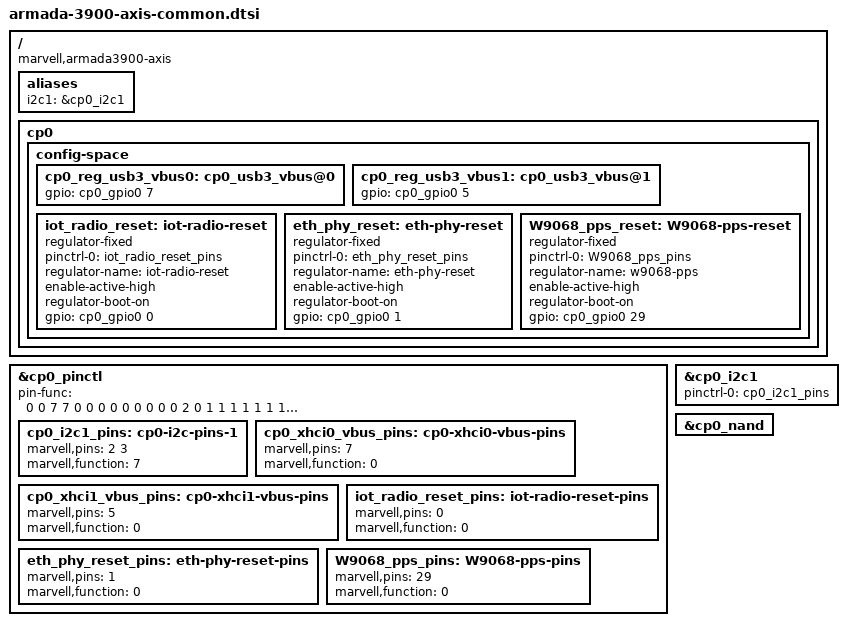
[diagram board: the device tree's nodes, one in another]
/*
 * Copyright (C) 2018 Marvell International Ltd.
 *
 * SPDX-License-Identifier:    GPL-2.0
 * https://spdx.org/licenses
 */

#include "armada-3900-db.dtsi"

/ {
	compatible = "marvell,armada3900-axis", "marvell,armada7040",
		     "marvell,armada-ap806-quad", "marvell,armada-ap806";

	aliases {
		i2c1 = &cp0_i2c1;
	};

	cp0 {
		config-space {
			cp0_reg_usb3_vbus0: cp0_usb3_vbus@0 {
				gpio = <&cp0_gpio0 7 GPIO_ACTIVE_HIGH>;
			};

			cp0_reg_usb3_vbus1: cp0_usb3_vbus@1 {
				gpio = <&cp0_gpio0 5 GPIO_ACTIVE_HIGH>;
			};

			iot_radio_reset: iot-radio-reset {
				compatible = "regulator-fixed";
				pinctrl-names = "default";
				pinctrl-0 = <&iot_radio_reset_pins>;
				regulator-name = "iot-radio-reset";
				enable-active-high;
				regulator-boot-on;
				gpio = <&cp0_gpio0 0 GPIO_ACTIVE_HIGH>;
			};

			eth_phy_reset: eth-phy-reset {
				compatible = "regulator-fixed";
				pinctrl-names = "default";
				pinctrl-0 = <&eth_phy_reset_pins>;
				regulator-name = "eth-phy-reset";
				enable-active-high;
				regulator-boot-on;
				gpio = <&cp0_gpio0 1 GPIO_ACTIVE_HIGH>;
			};

			W9068_pps_reset: W9068-pps-reset {
				compatible = "regulator-fixed";
				pinctrl-names = "default";
				pinctrl-0 = <&W9068_pps_pins>;
				regulator-name = "w9068-pps";
				enable-active-high;
				regulator-boot-on;
				gpio = <&cp0_gpio0 29 GPIO_ACTIVE_HIGH>;
			};
		};
	};
};

/*
 * CP related configuration
 */
&cp0_pinctl {
		/* MPP Bus:
		 *   I2C1    [2,3]
		 *   USB     [5,7]
		 *   NAND    [13,15-27]
		 *   SMI     [32,34]
		 *   XSMI    [35-36]
		 *   I2C0    [37-38]
		 *   UART1   [46-47,49,58]
		 *   IHB     [56-57]
		 *   UART0   [59-62]
		 */
		/*   0   1   2   3   4   5   6   7   8   9 */
	pin-func = < 0   0   7   7   0   0   0   0   0   0
		     0   0   0   2   0   1   1   1   1   1
		     1   1   1   1   1   1   1   1   0   0
		     0   0   7   0   7   7   7   2   2   0
		     0   0   0   0   0   0   7   7   0   7
		     0   0   0   0   0   0   0   0   7   7
		     7   7   7>;

	cp0_i2c1_pins: cp0-i2c-pins-1 {
		marvell,pins = < 2 3 >;
		marvell,function = <7>;
	};

	cp0_xhci0_vbus_pins: cp0-xhci0-vbus-pins {
		marvell,pins = <7>;
		marvell,function = <0>;
	};

	cp0_xhci1_vbus_pins: cp0-xhci1-vbus-pins {
		marvell,pins = <5>;
		marvell,function = <0>;
	};

	iot_radio_reset_pins: iot-radio-reset-pins {
		marvell,pins = <0>;
		marvell,function = <0>;
	};

	eth_phy_reset_pins: eth-phy-reset-pins {
		marvell,pins = <1>;
		marvell,function = <0>;
	};

	W9068_pps_pins: W9068-pps-pins {
		marvell,pins = <29>;
		marvell,function = <0>;
	};
};

&cp0_i2c1 {
	status = "okay";
	pinctrl-names = "default";
	pinctrl-0 = <&cp0_i2c1_pins>;
};


&cp0_nand {
	status = "okay";
};
